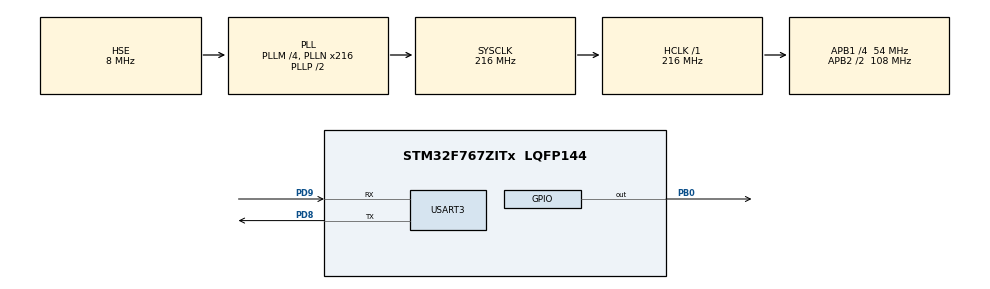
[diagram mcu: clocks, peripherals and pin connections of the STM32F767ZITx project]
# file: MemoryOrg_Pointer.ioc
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Mcu.Family=STM32F7
Mcu.Name=STM32F767ZITx
Mcu.Package=LQFP144
NVIC.PriorityGroup=NVIC_PRIORITYGROUP_4
PB0.Signal=GPIO_Output
PD8.Mode=Asynchronous
PD8.Signal=USART3_TX
PD9.Mode=Asynchronous
PD9.Signal=USART3_RX
PH0/OSC_IN.Mode=HSE-External-Oscillator
PH0/OSC_IN.Signal=RCC_OSC_IN
PH1/OSC_OUT.Mode=HSE-External-Oscillator
PH1/OSC_OUT.Signal=RCC_OSC_OUT
ProjectManager.HeapSize=0x200
ProjectManager.StackSize=0x400
ProjectManager.TargetToolchain=STM32CubeIDE
RCC.AHBFreq_Value=216000000
RCC.APB1CLKDivider=RCC_HCLK_DIV4
RCC.APB1Freq_Value=54000000
RCC.APB1TimFreq_Value=108000000
RCC.APB2CLKDivider=RCC_HCLK_DIV2
RCC.APB2Freq_Value=108000000
RCC.APB2TimFreq_Value=216000000
RCC.CortexFreq_Value=216000000
RCC.HCLKFreq_Value=216000000
RCC.HSE_VALUE=8000000
RCC.HSI_VALUE=16000000
RCC.LSE_VALUE=32768
RCC.PLLM=4
RCC.PLLN=216
RCC.PLLSourceVirtual=RCC_PLLSOURCE_HSE
RCC.SYSCLKFreq_VALUE=216000000
RCC.SYSCLKSource=RCC_SYSCLKSOURCE_PLLCLK
RCC.USBFreq_Value=216000000
RCC.VCOOutputFreq_Value=432000000
USART3.VirtualMode-Asynchronous=VM_ASYNC
board=custom

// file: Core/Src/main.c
/* USER CODE BEGIN Header */
/**
  ******************************************************************************
  * @file           : main.c
  * @brief          : Main program body
  ******************************************************************************
  * @author			: Jabed-Akhtar (GitHub)
  * @date			: 24.10.2022
  ******************************************************************************
  * @attention
  *		-> ---
  * Imp note:
  * 	- ---
  *
  * Description:
  * 	- Data/Value used for testing: 0x11223344
  * 	- Output:
  * 			Value(1-Byte)	| 	Memeory-Adress
  * 			--------------- | ----------------
  * 			0x44			|	537395124
  * 			0x33			|	537395125
  * 			0x22			|	537395126
  * 			0x11			|	537395127
  *		- Result: Little Endian
  *
  ******************************************************************************
  */
/* USER CODE END Header */
#include "main.h"

/* USER CODE BEGIN Includes */
#include <stdio.h>
/* USER CODE END Includes */

/* USER CODE BEGIN PD */
#define SRAM1_BASE_ADDR 0x20020000
/* USER CODE END PD */

UART_HandleTypeDef huart3;

void SystemClock_Config(void);
static void MX_GPIO_Init(void);
static void MX_USART3_UART_Init(void);

int main(void)
{

  /* MCU Configuration--------------------------------------------------------*/

  /* Reset of all peripherals, Initializes the Flash interface and the Systick. */
  HAL_Init();

  /* Configure the system clock */
  SystemClock_Config();

  /* Initialize all configured peripherals */
  MX_GPIO_Init();
  MX_USART3_UART_Init();
  /* USER CODE BEGIN 2 */

  char stri[] = "\n---------- Programm started!!! ----------\n\n\r";
  HAL_UART_Transmit(&huart3, (uint8_t*)stri, strlen(stri), HAL_MAX_DELAY);

  unsigned int value = 0x11223344;
  char *r = (char *) &value;
  int i;
  char buffer[50];

  // Saving value 5 kB above the base of SRAM1
  unsigned int valSave = 0xabcd;
  unsigned int addressValToAdd = 0x5000; // 5 kB
  unsigned int addressValAdded = SRAM1_BASE_ADDR + addressValToAdd;

  /* USER CODE END 2 */

  /* Infinite loop */
  while (1)
  {

    /* USER CODE BEGIN 3 */
//	  __WFI();
	  HAL_Delay(1000);
	  HAL_GPIO_TogglePin(GPIOB, GPIO_PIN_0);
	  for(i=0; i<4; i++)
	  {
//		  printf("Address of 0x%x = %d \n", r[i], &r[i]);
		  sprintf(buffer, "0x%x = %d \n\r", r[i], &r[i]);
		  HAL_UART_Transmit(&huart3, (uint8_t*)buffer, strlen(buffer), HAL_MAX_DELAY);
		  HAL_Delay(500);
	  }
	  memset(buffer, 0, sizeof(buffer));
	  sprintf(buffer, "0x%x = %d \n\r", addressValAdded, &addressValAdded);
	  HAL_UART_Transmit(&huart3, (uint8_t*)buffer, strlen(buffer), HAL_MAX_DELAY);
	  HAL_Delay(500);
  }
  /* USER CODE END 3 */
}

void SystemClock_Config(void)
{
  RCC_OscInitTypeDef RCC_OscInitStruct = {0};
  RCC_ClkInitTypeDef RCC_ClkInitStruct = {0};
  RCC_PeriphCLKInitTypeDef PeriphClkInitStruct = {0};

  /** Configure the main internal regulator output voltage
  */
  __HAL_RCC_PWR_CLK_ENABLE();
  __HAL_PWR_VOLTAGESCALING_CONFIG(PWR_REGULATOR_VOLTAGE_SCALE1);
  /** Initializes the RCC Oscillators according to the specified parameters
  * in the RCC_OscInitTypeDef structure.
  */
  RCC_OscInitStruct.OscillatorType = RCC_OSCILLATORTYPE_HSE;
  RCC_OscInitStruct.HSEState = RCC_HSE_ON;
  RCC_OscInitStruct.PLL.PLLState = RCC_PLL_ON;
  RCC_OscInitStruct.PLL.PLLSource = RCC_PLLSOURCE_HSE;
  RCC_OscInitStruct.PLL.PLLM = 4;
  RCC_OscInitStruct.PLL.PLLN = 216;
  RCC_OscInitStruct.PLL.PLLP = RCC_PLLP_DIV2;
  RCC_OscInitStruct.PLL.PLLQ = 2;
  if (HAL_RCC_OscConfig(&RCC_OscInitStruct) != HAL_OK)
  {
    Error_Handler();
  }
  /** Activate the Over-Drive mode
  */
  if (HAL_PWREx_EnableOverDrive() != HAL_OK)
  {
    Error_Handler();
  }
  /** Initializes the CPU, AHB and APB buses clocks
  */
  RCC_ClkInitStruct.ClockType = RCC_CLOCKTYPE_HCLK|RCC_CLOCKTYPE_SYSCLK
                              |RCC_CLOCKTYPE_PCLK1|RCC_CLOCKTYPE_PCLK2;
  RCC_ClkInitStruct.SYSCLKSource = RCC_SYSCLKSOURCE_PLLCLK;
  RCC_ClkInitStruct.AHBCLKDivider = RCC_SYSCLK_DIV1;
  RCC_ClkInitStruct.APB1CLKDivider = RCC_HCLK_DIV4;
  RCC_ClkInitStruct.APB2CLKDivider = RCC_HCLK_DIV2;

  if (HAL_RCC_ClockConfig(&RCC_ClkInitStruct, FLASH_LATENCY_7) != HAL_OK)
  {
    Error_Handler();
  }
  PeriphClkInitStruct.PeriphClockSelection = RCC_PERIPHCLK_USART3;
  PeriphClkInitStruct.Usart3ClockSelection = RCC_USART3CLKSOURCE_PCLK1;
  if (HAL_RCCEx_PeriphCLKConfig(&PeriphClkInitStruct) != HAL_OK)
  {
    Error_Handler();
  }
}

static void MX_USART3_UART_Init(void)
{

  huart3.Instance = USART3;
  huart3.Init.BaudRate = 115200;
  huart3.Init.WordLength = UART_WORDLENGTH_8B;
  huart3.Init.StopBits = UART_STOPBITS_1;
  huart3.Init.Parity = UART_PARITY_NONE;
  huart3.Init.Mode = UART_MODE_TX_RX;
  huart3.Init.HwFlowCtl = UART_HWCONTROL_NONE;
  huart3.Init.OverSampling = UART_OVERSAMPLING_16;
  huart3.Init.OneBitSampling = UART_ONE_BIT_SAMPLE_DISABLE;
  huart3.AdvancedInit.AdvFeatureInit = UART_ADVFEATURE_NO_INIT;
  if (HAL_UART_Init(&huart3) != HAL_OK)
  {
    Error_Handler();
  }

}

static void MX_GPIO_Init(void)
{
  GPIO_InitTypeDef GPIO_InitStruct = {0};

  /* GPIO Ports Clock Enable */
  __HAL_RCC_GPIOH_CLK_ENABLE();
  __HAL_RCC_GPIOB_CLK_ENABLE();
  __HAL_RCC_GPIOD_CLK_ENABLE();

  /*Configure GPIO pin Output Level */
  HAL_GPIO_WritePin(GPIOB, GPIO_PIN_0, GPIO_PIN_RESET);

  /*Configure GPIO pin : PB0 */
  GPIO_InitStruct.Pin = GPIO_PIN_0;
  GPIO_InitStruct.Mode = GPIO_MODE_OUTPUT_PP;
  GPIO_InitStruct.Pull = GPIO_NOPULL;
  GPIO_InitStruct.Speed = GPIO_SPEED_FREQ_LOW;
  HAL_GPIO_Init(GPIOB, &GPIO_InitStruct);

}

void Error_Handler(void)
{
}

/************************ (C) COPYRIGHT STMicroelectronics *****END OF FILE****/
